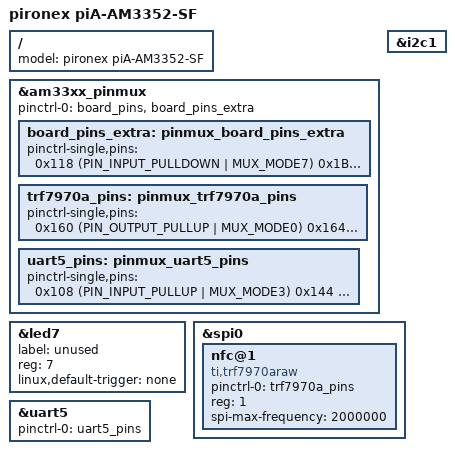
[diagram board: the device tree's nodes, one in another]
/*
 * Copyright (C) 2015 pironex GmbH (http://www.pironex.de)
 *
 * This program is free software; you can redistribute it and/or modify
 * it under the terms of the GNU General Public License version 2 as
 * published by the Free Software Foundation.
 */
/dts-v1/;

#include "am335x-pia-sf.dtsi"

/ {
	model = "pironex piA-AM3352-SF";

};

&am33xx_pinmux {
	pinctrl-names = "default";
	pinctrl-0 = <&board_pins &board_pins_extra>;

	board_pins_extra: pinmux_board_pins_extra {
		pinctrl-single,pins = <
			0x118 (PIN_INPUT_PULLDOWN | MUX_MODE7)	/* SP1ML-BOOT: mii1_rxdv.gpio3_4 */
			0x1B4 (PIN_INPUT_PULLUP | MUX_MODE7)	/* SP1ML-RESET: xdma_event_intr1.gpio0_20 */
			0x1E8 (PIN_INPUT_PULLUP | MUX_MODE7)	/* SP1ML-SHDN: emu1.gpio3_8 */
		>;
	};

	trf7970a_pins: pinmux_trf7970a_pins {
		pinctrl-single,pins = <
			0x160 (PIN_OUTPUT_PULLUP | MUX_MODE0)	/* CS  spi0_cs1.spi0_cs1 */
			0x164 (PIN_INPUT_PULLDOWN | MUX_MODE7)	/* IRQ ecap0_in_pwm0_out.gpio0_7 */ 
			0x1B0 (PIN_INPUT_PULLDOWN | MUX_MODE7)	/* EN  xdma_event_intr0.gpio0_19 */
			0x134 (PIN_INPUT_PULLDOWN | MUX_MODE7)	/* EN2 mii1_rxd3.gpio2_18 */
		>;
	};

	uart5_pins: pinmux_uart5_pins {
		pinctrl-single,pins = <
			0x108 (PIN_INPUT_PULLUP | MUX_MODE3)	/* mii1_col.uart5_rxd */
			0x144 (PIN_OUTPUT_PULLDOWN | MUX_MODE3)	/* rmii1_refclk.uart5_txd */
		>;
	};
};

&led7 {
	label = "unused";
	reg = <7>;
	linux,default-trigger = "none";
};

&i2c1 {
};

&spi0 {
//	nfc@1 {
//		pinctrl-0 = <&trf7970a_pins>;
//		pinctrl-names = "default";
//
//		compatible = "ti,trf7970a";
//		spi-max-frequency = <2000000>;
//		reg = <1>;
//
//		interrupt-parent = <&gpio0>;
//		interrupts = <7 IRQ_TYPE_EDGE_RISING>;
//		/*interrupts = <7 0>;*/
//		ti,enable-gpios = <&gpio0 19 GPIO_ACTIVE_HIGH>,
//				  <&gpio2 18 GPIO_ACTIVE_HIGH>;
//		vin-supply = <&vcc_5v0_in>;
//		vin-voltage-override = <5000000>;
//		autosuspend-delay = <30000>;
//		irq-status-read-quirk;
//		en2-rf-quirk;
//		t5t-rmb-extra-byte-quirk;
//		status = "okay";
//	};
	nfc@1 {
		pinctrl-0 = <&trf7970a_pins>;
		pinctrl-names = "default";
		compatible = "ti,trf7970araw";
		reg = <1>;
		spi-max-frequency = <2000000>;
		status = "ok";
	};

};

/* SP1ML-868 Radio */
&uart5 {
	pinctrl-names = "default";
	pinctrl-0 = <&uart5_pins>;

	status = "okay";
};
